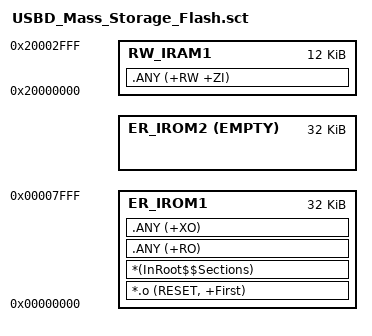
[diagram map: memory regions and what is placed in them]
; *************************************************************
; *** Scatter-Loading Description File generated by uVision ***
; *************************************************************

LR_IROM1 0x00000000 0x00010000  {    ; load region size_region
  ER_IROM1 0x00000000 0x00008000  {  ; load address = execution address
   *.o (RESET, +First)
   *(InRoot$$Sections)
   .ANY (+RO)
   .ANY (+XO)
  }
  
  ER_IROM2 +0 EMPTY 0x8000 { ;Create a free space to simulate flash disk 
							 ;Hardfault fault may raise while PC doing formatting
  						     ;if target device is with insufficient flash disk.
  }
  
  RW_IRAM1 0x20000000 0x00003000  {  ; RW data
   .ANY (+RW +ZI)
  }

}

